AUTOSAR XML (schema 4-2-2)
package /Components
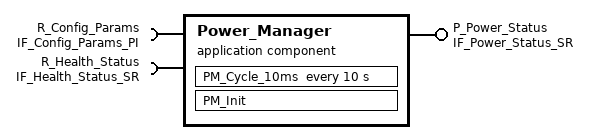
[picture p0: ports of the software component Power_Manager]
  application sw component type Power_Manager
    provide port P_Power_Status: provided-interface=IF_Power_Status_SR
    require port R_Config_Params: required-interface=IF_Config_Params_PI
    require port R_Health_Status: required-interface=IF_Health_Status_SR
    behavior Power_Manager_InternalBehavior
      init event PM_InitEvent: start-on-event=PM_Init
      timing event PM_Cyclic_10ms: start-on-event=PM_Cycle_10ms, period=10
      runnable PM_Init
        data-read-access:
          access Read_ECU_Temperature_Init: accessed-variable=R_Health_Status.temperature
          access Read_ECU_Voltage_Init: accessed-variable=R_Health_Status.voltage
        data-send-points:
          4 x access:
            Send_SOC_Init: accessed-variable=P_Power_Status.soc
            Send_Power_Available_Init: accessed-variable=P_Power_Status.power_available
            Send_Regen_Limit_Init: accessed-variable=P_Power_Status.regen_limit
            Send_Thermal_Derate_Init: accessed-variable=P_Power_Status.thermal_derate
        data-write-access:
          4 x access:
            Write_SOC_Init: accessed-variable=P_Power_Status.soc
            Write_Power_Available_Init: accessed-variable=P_Power_Status.power_available
            Write_Regen_Limit_Init: accessed-variable=P_Power_Status.regen_limit
            Write_Thermal_Derate_Init: accessed-variable=P_Power_Status.thermal_derate
        4 x parameter access:
          Access_Controller_Gains_Init: accessed-parameter=R_Config_Params.controller_gains
          Access_Limits_Init: accessed-parameter=R_Config_Params.limits
          Access_Security_Policy_Init: accessed-parameter=R_Config_Params.security_policy
          Access_Key_Ref_Init: accessed-parameter=R_Config_Params.key_ref
      runnable PM_Cycle_10ms: minimum-start-interval=10
        data-read-access:
          4 x access:
            Read_ECU_Health_Cycle: accessed-variable=R_Health_Status.ecu_health
            Read_Temperature_Cycle: accessed-variable=R_Health_Status.temperature
            Read_Voltage_Cycle: accessed-variable=R_Health_Status.voltage
            Read_FaultCode_Cycle: accessed-variable=R_Health_Status.fault_code
        data-send-points:
          4 x access:
            Send_SOC_Cycle: accessed-variable=P_Power_Status.soc
            Send_Power_Available_Cycle: accessed-variable=P_Power_Status.power_available
            Send_Regen_Limit_Cycle: accessed-variable=P_Power_Status.regen_limit
            Send_Thermal_Derate_Cycle: accessed-variable=P_Power_Status.thermal_derate
        data-write-access:
          4 x access:
            Write_SOC_Cycle: accessed-variable=P_Power_Status.soc
            Write_Power_Available_Cycle: accessed-variable=P_Power_Status.power_available
            Write_Regen_Limit_Cycle: accessed-variable=P_Power_Status.regen_limit
            Write_Thermal_Derate_Cycle: accessed-variable=P_Power_Status.thermal_derate
        parameter access Access_Limits_Cycle: accessed-parameter=R_Config_Params.limits
        parameter access Access_Controller_Gains_Cycle: accessed-parameter=R_Config_Params.controller_gains
